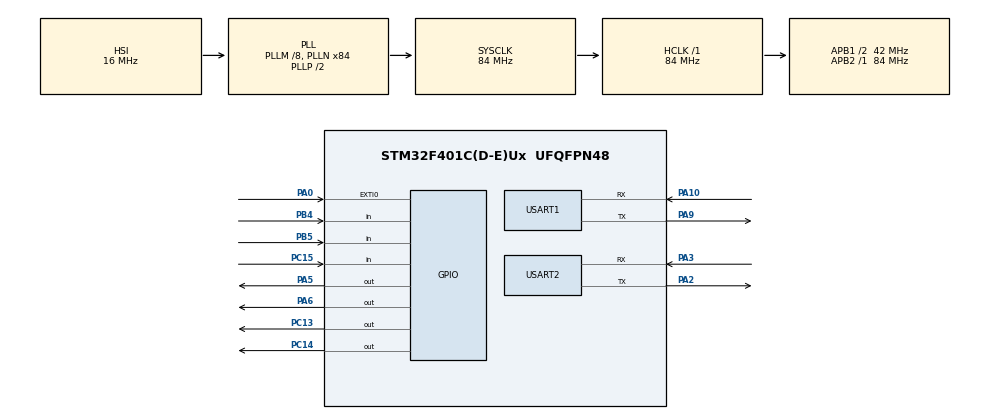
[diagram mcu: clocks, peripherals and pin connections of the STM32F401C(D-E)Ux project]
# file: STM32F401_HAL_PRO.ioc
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Dma.Request0=USART1_TX
Dma.Request1=USART1_RX
Dma.Request2=USART2_RX
Dma.Request3=USART2_TX
Dma.USART1_RX.1.Direction=DMA_PERIPH_TO_MEMORY
Dma.USART1_RX.1.FIFOMode=DMA_FIFOMODE_DISABLE
Dma.USART1_RX.1.Instance=DMA2_Stream2
Dma.USART1_RX.1.MemDataAlignment=DMA_MDATAALIGN_BYTE
Dma.USART1_RX.1.MemInc=DMA_MINC_ENABLE
Dma.USART1_RX.1.Mode=DMA_NORMAL
Dma.USART1_RX.1.PeriphDataAlignment=DMA_PDATAALIGN_BYTE
Dma.USART1_RX.1.PeriphInc=DMA_PINC_DISABLE
Dma.USART1_RX.1.Priority=DMA_PRIORITY_LOW
Dma.USART1_TX.0.Direction=DMA_MEMORY_TO_PERIPH
Dma.USART1_TX.0.FIFOMode=DMA_FIFOMODE_DISABLE
Dma.USART1_TX.0.Instance=DMA2_Stream7
Dma.USART1_TX.0.MemDataAlignment=DMA_MDATAALIGN_BYTE
Dma.USART1_TX.0.MemInc=DMA_MINC_ENABLE
Dma.USART1_TX.0.Mode=DMA_NORMAL
Dma.USART1_TX.0.PeriphDataAlignment=DMA_PDATAALIGN_BYTE
Dma.USART1_TX.0.PeriphInc=DMA_PINC_DISABLE
Dma.USART1_TX.0.Priority=DMA_PRIORITY_LOW
Dma.USART2_RX.2.Direction=DMA_PERIPH_TO_MEMORY
Dma.USART2_RX.2.FIFOMode=DMA_FIFOMODE_DISABLE
Dma.USART2_RX.2.Instance=DMA1_Stream5
Dma.USART2_RX.2.MemDataAlignment=DMA_MDATAALIGN_BYTE
Dma.USART2_RX.2.MemInc=DMA_MINC_ENABLE
Dma.USART2_RX.2.Mode=DMA_NORMAL
Dma.USART2_RX.2.PeriphDataAlignment=DMA_PDATAALIGN_BYTE
Dma.USART2_RX.2.PeriphInc=DMA_PINC_DISABLE
Dma.USART2_RX.2.Priority=DMA_PRIORITY_LOW
Dma.USART2_TX.3.Direction=DMA_MEMORY_TO_PERIPH
Dma.USART2_TX.3.FIFOMode=DMA_FIFOMODE_DISABLE
Dma.USART2_TX.3.Instance=DMA1_Stream6
Dma.USART2_TX.3.MemDataAlignment=DMA_MDATAALIGN_BYTE
Dma.USART2_TX.3.MemInc=DMA_MINC_ENABLE
Dma.USART2_TX.3.Mode=DMA_NORMAL
Dma.USART2_TX.3.PeriphDataAlignment=DMA_PDATAALIGN_BYTE
Dma.USART2_TX.3.PeriphInc=DMA_PINC_DISABLE
Dma.USART2_TX.3.Priority=DMA_PRIORITY_LOW
Mcu.Family=STM32F4
Mcu.Name=STM32F401C(D-E)Ux
Mcu.Package=UFQFPN48
NVIC.DMA1_Stream5_IRQn=true\:0\:0\:false\:false\:true\:false\:true
NVIC.DMA1_Stream6_IRQn=true\:0\:0\:false\:false\:true\:false\:true
NVIC.DMA2_Stream2_IRQn=true\:0\:0\:false\:false\:true\:false\:true
NVIC.DMA2_Stream7_IRQn=true\:0\:0\:false\:false\:true\:false\:true
NVIC.EXTI0_IRQn=true\:0\:0\:false\:false\:true\:true\:true
NVIC.PriorityGroup=NVIC_PRIORITYGROUP_4
NVIC.TIM1_UP_TIM10_IRQn=true\:0\:0\:false\:false\:true\:true\:true
NVIC.USART1_IRQn=true\:0\:0\:false\:false\:true\:true\:true
NVIC.USART2_IRQn=true\:0\:0\:false\:false\:true\:true\:true
PA0-WKUP.Signal=GPXTI0
PA10.Mode=Asynchronous
PA10.Signal=USART1_RX
PA13.Mode=Serial_Wire
PA13.Signal=SYS_JTMS-SWDIO
PA14.Mode=Serial_Wire
PA14.Signal=SYS_JTCK-SWCLK
PA2.Mode=Asynchronous
PA2.Signal=USART2_TX
PA3.Mode=Asynchronous
PA3.Signal=USART2_RX
PA5.Signal=GPIO_Output
PA6.Signal=GPIO_Output
PA9.Mode=Asynchronous
PA9.Signal=USART1_TX
PB4.Signal=GPIO_Input
PB5.Signal=GPIO_Input
PC13-ANTI_TAMP.Signal=GPIO_Output
PC14-OSC32_IN.Signal=GPIO_Output
PC15-OSC32_OUT.Signal=GPIO_Input
PH0\ -\ OSC_IN.Mode=HSE-External-Oscillator
PH0\ -\ OSC_IN.Signal=RCC_OSC_IN
PH1\ -\ OSC_OUT.Mode=HSE-External-Oscillator
PH1\ -\ OSC_OUT.Signal=RCC_OSC_OUT
ProjectManager.HeapSize=0x200
ProjectManager.StackSize=0x400
ProjectManager.TargetToolchain=MDK-ARM V5.32
RCC.48MHZClocksFreq_Value=42000000
RCC.AHBFreq_Value=84000000
RCC.APB1CLKDivider=RCC_HCLK_DIV2
RCC.APB1Freq_Value=42000000
RCC.APB1TimFreq_Value=84000000
RCC.APB2Freq_Value=84000000
RCC.APB2TimFreq_Value=84000000
RCC.CortexFreq_Value=84000000
RCC.HCLKFreq_Value=84000000
RCC.HSE_VALUE=16000000
RCC.HSI_VALUE=16000000
RCC.LSE_VALUE=32768
RCC.PLLM=8
RCC.PLLN=84
RCC.SYSCLKFreq_VALUE=84000000
RCC.SYSCLKSource=RCC_SYSCLKSOURCE_PLLCLK
RCC.VCOOutputFreq_Value=168000000
TIM10.Period=999
TIM10.Prescaler=83-1
USART1.VirtualMode=VM_ASYNC
USART2.VirtualMode=VM_ASYNC
VP_TIM10_VS_ClockSourceINT.Mode=Enable_Timer
board=custom

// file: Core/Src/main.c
/* USER CODE BEGIN Header */
/**
  ******************************************************************************
  * @file           : main.c
  * @brief          : Main program body
  ******************************************************************************
  * @attention
  *
  * Copyright (c) 2022 STMicroelectronics.
  * All rights reserved.
  *
  * This software is licensed under terms that can be found in the LICENSE file
  * in the root directory of this software component.
  * If no LICENSE file comes with this software, it is provided AS-IS.
  *
  ******************************************************************************
  */
/* USER CODE END Header */
#include "main.h"

/* USER CODE BEGIN Includes */
#include "myusart.h"
#include "malloc.h"
#include "include.h"
/* USER CODE END Includes */

TIM_HandleTypeDef htim10;

UART_HandleTypeDef huart1;
UART_HandleTypeDef huart2;
DMA_HandleTypeDef hdma_usart1_tx;
DMA_HandleTypeDef hdma_usart1_rx;
DMA_HandleTypeDef hdma_usart2_rx;
DMA_HandleTypeDef hdma_usart2_tx;

void SystemClock_Config(void);
static void MX_GPIO_Init(void);
static void MX_TIM10_Init(void);
static void MX_USART1_UART_Init(void);
static void MX_DMA_Init(void);
static void MX_USART2_UART_Init(void);
/* USER CODE BEGIN PFP */
extern uint16_t lastmyms,myms,delayms;
RingBuff_t Key_ringBuff;//创建一个ringBuff的缓冲区,用于缓存按键
/* USER CODE END PFP */

int main(void)
{

  /* MCU Configuration--------------------------------------------------------*/

  /* Reset of all peripherals, Initializes the Flash interface and the Systick. */
  HAL_Init();

  /* Configure the system clock */
  SystemClock_Config();

  /* Initialize all configured peripherals */
  MX_GPIO_Init();
	MX_DMA_Init();
  MX_TIM10_Init();
  MX_USART1_UART_Init();
  MX_USART2_UART_Init();
  /* USER CODE BEGIN 2 */
	HAL_TIM_Base_Start_IT(&htim10);
//	uint8_t *p;
	my_mem_init(0);
	RingBuff_Init(&Key_ringBuff);

	MultiTimerInstall(Get_Tick);//安装定时器驱动，配置时间戳
	MultiTimer mytimer1,mytimer2,mytimer3;//实例化3个软件定时器
	MultiTimerStart(&mytimer1, 1000, MyTimer1Callback, "1000ms CYCLE timer");
	MultiTimerStart(&mytimer2, 50, MyTimer2Callback, "1000ms CYCLE timer");
	MultiTimerStart(&mytimer3, 5000, MyTimer3Callback, "1000ms CYCLE timer");

  /* USER CODE END 2 */

  /* Infinite loop */
  while (1)
  {

    /* USER CODE BEGIN 3 */
		MultiTimerYield();
//		p = mymalloc(0,500);//申请内存
//		sprintf((char*)p,"你好呀，好好好啊");
//		printf("%s\r\n",p);
//		printf("内存利用率:%d%%\r\n",my_mem_perused(0));
////		HAL_GPIO_WritePin (GPIOA,GPIO_PIN_5,GPIO_PIN_RESET);
////		HAL_GPIO_WritePin (GPIOA,GPIO_PIN_6,GPIO_PIN_RESET);
////		HAL_GPIO_WritePin (GPIOC,GPIO_PIN_13,GPIO_PIN_RESET);
////		HAL_GPIO_WritePin (GPIOC,GPIO_PIN_14,GPIO_PIN_RESET);
//		HAL_Delay (500);
//
//		myfree(0,p);//释放内存
//		printf("%s\r\n",p);
//		printf("内存利用率:%d%%\r\n",my_mem_perused(0));
////		HAL_GPIO_WritePin (GPIOA,GPIO_PIN_5,GPIO_PIN_SET);
////		HAL_GPIO_WritePin (GPIOA,GPIO_PIN_6,GPIO_PIN_SET);
////		HAL_GPIO_WritePin (GPIOC,GPIO_PIN_13,GPIO_PIN_SET);
////		HAL_GPIO_WritePin (GPIOC,GPIO_PIN_14,GPIO_PIN_SET);
//		printf("delay = %d us \r\n",delayms);
//		HAL_Delay (500);
  }
  /* USER CODE END 3 */
}

void SystemClock_Config(void)
{
  RCC_OscInitTypeDef RCC_OscInitStruct = {0};
  RCC_ClkInitTypeDef RCC_ClkInitStruct = {0};

  /** Configure the main internal regulator output voltage
  */
  __HAL_RCC_PWR_CLK_ENABLE();
  __HAL_PWR_VOLTAGESCALING_CONFIG(PWR_REGULATOR_VOLTAGE_SCALE2);
  /** Initializes the RCC Oscillators according to the specified parameters
  * in the RCC_OscInitTypeDef structure.
  */
  RCC_OscInitStruct.OscillatorType = RCC_OSCILLATORTYPE_HSI;
  RCC_OscInitStruct.HSIState = RCC_HSI_ON;
  RCC_OscInitStruct.HSICalibrationValue = RCC_HSICALIBRATION_DEFAULT;
  RCC_OscInitStruct.PLL.PLLState = RCC_PLL_ON;
  RCC_OscInitStruct.PLL.PLLSource = RCC_PLLSOURCE_HSI;
  RCC_OscInitStruct.PLL.PLLM = 8;
  RCC_OscInitStruct.PLL.PLLN = 84;
  RCC_OscInitStruct.PLL.PLLP = RCC_PLLP_DIV2;
  RCC_OscInitStruct.PLL.PLLQ = 4;
  if (HAL_RCC_OscConfig(&RCC_OscInitStruct) != HAL_OK)
  {
    Error_Handler();
  }
  /** Initializes the CPU, AHB and APB buses clocks
  */
  RCC_ClkInitStruct.ClockType = RCC_CLOCKTYPE_HCLK|RCC_CLOCKTYPE_SYSCLK
                              |RCC_CLOCKTYPE_PCLK1|RCC_CLOCKTYPE_PCLK2;
  RCC_ClkInitStruct.SYSCLKSource = RCC_SYSCLKSOURCE_PLLCLK;
  RCC_ClkInitStruct.AHBCLKDivider = RCC_SYSCLK_DIV1;
  RCC_ClkInitStruct.APB1CLKDivider = RCC_HCLK_DIV2;
  RCC_ClkInitStruct.APB2CLKDivider = RCC_HCLK_DIV1;

  if (HAL_RCC_ClockConfig(&RCC_ClkInitStruct, FLASH_LATENCY_2) != HAL_OK)
  {
    Error_Handler();
  }
}

static void MX_TIM10_Init(void)
{

  htim10.Instance = TIM10;
  htim10.Init.Prescaler = 83-1;
  htim10.Init.CounterMode = TIM_COUNTERMODE_UP;
  htim10.Init.Period = 999;
  htim10.Init.ClockDivision = TIM_CLOCKDIVISION_DIV1;
  htim10.Init.AutoReloadPreload = TIM_AUTORELOAD_PRELOAD_DISABLE;
  if (HAL_TIM_Base_Init(&htim10) != HAL_OK)
  {
    Error_Handler();
  }

}

static void MX_USART1_UART_Init(void)
{

  huart1.Instance = USART1;
  huart1.Init.BaudRate = 115200;
  huart1.Init.WordLength = UART_WORDLENGTH_8B;
  huart1.Init.StopBits = UART_STOPBITS_1;
  huart1.Init.Parity = UART_PARITY_NONE;
  huart1.Init.Mode = UART_MODE_TX_RX;
  huart1.Init.HwFlowCtl = UART_HWCONTROL_NONE;
  huart1.Init.OverSampling = UART_OVERSAMPLING_16;
  if (HAL_UART_Init(&huart1) != HAL_OK)
  {
    Error_Handler();
  }

}

static void MX_USART2_UART_Init(void)
{

  huart2.Instance = USART2;
  huart2.Init.BaudRate = 115200;
  huart2.Init.WordLength = UART_WORDLENGTH_8B;
  huart2.Init.StopBits = UART_STOPBITS_1;
  huart2.Init.Parity = UART_PARITY_NONE;
  huart2.Init.Mode = UART_MODE_TX_RX;
  huart2.Init.HwFlowCtl = UART_HWCONTROL_NONE;
  huart2.Init.OverSampling = UART_OVERSAMPLING_16;
  if (HAL_UART_Init(&huart2) != HAL_OK)
  {
    Error_Handler();
  }

}

static void MX_DMA_Init(void)
{

  /* DMA controller clock enable */
  __HAL_RCC_DMA2_CLK_ENABLE();
  __HAL_RCC_DMA1_CLK_ENABLE();

  /* DMA interrupt init */
  /* DMA1_Stream5_IRQn interrupt configuration */
  HAL_NVIC_SetPriority(DMA1_Stream5_IRQn, 0, 0);
  HAL_NVIC_EnableIRQ(DMA1_Stream5_IRQn);
  /* DMA1_Stream6_IRQn interrupt configuration */
  HAL_NVIC_SetPriority(DMA1_Stream6_IRQn, 0, 0);
  HAL_NVIC_EnableIRQ(DMA1_Stream6_IRQn);
  /* DMA2_Stream2_IRQn interrupt configuration */
  HAL_NVIC_SetPriority(DMA2_Stream2_IRQn, 0, 0);
  HAL_NVIC_EnableIRQ(DMA2_Stream2_IRQn);
  /* DMA2_Stream7_IRQn interrupt configuration */
  HAL_NVIC_SetPriority(DMA2_Stream7_IRQn, 0, 0);
  HAL_NVIC_EnableIRQ(DMA2_Stream7_IRQn);

}

static void MX_GPIO_Init(void)
{
  GPIO_InitTypeDef GPIO_InitStruct = {0};

  /* GPIO Ports Clock Enable */
  __HAL_RCC_GPIOC_CLK_ENABLE();
  __HAL_RCC_GPIOH_CLK_ENABLE();
  __HAL_RCC_GPIOA_CLK_ENABLE();
  __HAL_RCC_GPIOB_CLK_ENABLE();

  /*Configure GPIO pin Output Level */
  HAL_GPIO_WritePin(GPIOC, GPIO_PIN_13|GPIO_PIN_14, GPIO_PIN_RESET);

  /*Configure GPIO pin Output Level */
  HAL_GPIO_WritePin(GPIOA, GPIO_PIN_5|GPIO_PIN_6, GPIO_PIN_RESET);

  /*Configure GPIO pins : PC13 PC14 */
  GPIO_InitStruct.Pin = GPIO_PIN_13|GPIO_PIN_14;
  GPIO_InitStruct.Mode = GPIO_MODE_OUTPUT_PP;
  GPIO_InitStruct.Pull = GPIO_NOPULL;
  GPIO_InitStruct.Speed = GPIO_SPEED_FREQ_LOW;
  HAL_GPIO_Init(GPIOC, &GPIO_InitStruct);

  /*Configure GPIO pin : PC15 */
  GPIO_InitStruct.Pin = GPIO_PIN_15;
  GPIO_InitStruct.Mode = GPIO_MODE_INPUT;
  GPIO_InitStruct.Pull = GPIO_NOPULL;
  HAL_GPIO_Init(GPIOC, &GPIO_InitStruct);

  /*Configure GPIO pin : PA0 */
  GPIO_InitStruct.Pin = GPIO_PIN_0;
  GPIO_InitStruct.Mode = GPIO_MODE_IT_RISING;
  GPIO_InitStruct.Pull = GPIO_NOPULL;
  HAL_GPIO_Init(GPIOA, &GPIO_InitStruct);

  /*Configure GPIO pins : PA5 PA6 */
  GPIO_InitStruct.Pin = GPIO_PIN_5|GPIO_PIN_6;
  GPIO_InitStruct.Mode = GPIO_MODE_OUTPUT_PP;
  GPIO_InitStruct.Pull = GPIO_NOPULL;
  GPIO_InitStruct.Speed = GPIO_SPEED_FREQ_LOW;
  HAL_GPIO_Init(GPIOA, &GPIO_InitStruct);

  /*Configure GPIO pins : PB4 PB5 */
  GPIO_InitStruct.Pin = GPIO_PIN_4|GPIO_PIN_5;
  GPIO_InitStruct.Mode = GPIO_MODE_INPUT;
  GPIO_InitStruct.Pull = GPIO_NOPULL;
  HAL_GPIO_Init(GPIOB, &GPIO_InitStruct);

  /* EXTI interrupt init*/
  HAL_NVIC_SetPriority(EXTI0_IRQn, 0, 0);
  HAL_NVIC_EnableIRQ(EXTI0_IRQn);

}

void Error_Handler(void)
{
  __disable_irq();
  while (1)
  {
  }
}
